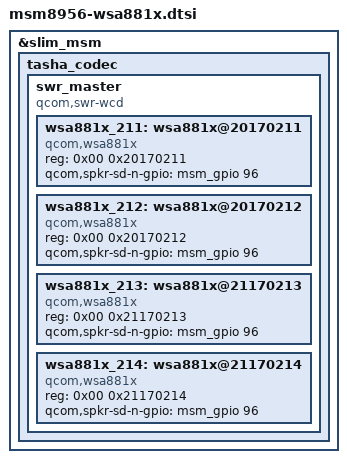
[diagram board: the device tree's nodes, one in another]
// SPDX-License-Identifier: GPL-2.0
// Copyright (c) 2015-2016, The Linux Foundation. All rights reserved.
// Copyright (c) 2022, Benarji Anand <benarji385@gmail.com>

&slim_msm {
	tasha_codec {
		swr_master {
			compatible = "qcom,swr-wcd";
			#address-cells = <2>;
			#size-cells = <0>;

			wsa881x_211: wsa881x@20170211 {
				compatible = "qcom,wsa881x";
				reg = <0x00 0x20170211>;
				qcom,spkr-sd-n-gpio = <&msm_gpio 96 0>;

			};

			wsa881x_212: wsa881x@20170212 {
				compatible = "qcom,wsa881x";
				reg = <0x00 0x20170212>;
				qcom,spkr-sd-n-gpio = <&msm_gpio 96 0>;

			};

			wsa881x_213: wsa881x@21170213 {
				compatible = "qcom,wsa881x";
				reg = <0x00 0x21170213>;
				qcom,spkr-sd-n-gpio = <&msm_gpio 96 0>;

			};

			wsa881x_214: wsa881x@21170214 {
				compatible = "qcom,wsa881x";
				reg = <0x00 0x21170214>;
				qcom,spkr-sd-n-gpio = <&msm_gpio 96 0>;

			};
		};
	};
};
